# M051BN_v1 register map
File version: 1.0
Registers are 32-bit, read-write, reset 0x0 unless marked. A register's access mark holds for its fields unless they carry their own. Offsets are from the block's base; [hi:lo] are bit positions; {n}, {i} and the like mark numbered series.

## INT — INT Register Map
Base 0x50000300
0x00 IRQ0_SRC ro reset not defined — IRQ0 (BOD) Interrupt Source Identity
  [2:0] INT_SRC — IRQ0 Source Identity. Note: When the interrupt flag is cleared, the corresponding bits will be cleared automatically.
    0=IRQ0 source is not from BOD interrupt (BOD_INT); 1=IRQ0 source is from BOD interrupt (BOD_INT)
0x04 IRQ1_SRC ro reset not defined — IRQ1 (WDT) Interrupt Source Identity
  [2:0] INT_SRC — IRQ1 Source Identity. Note: When the interrupt flag is cleared, the corresponding bits will be cleared automatically.
    0=IRQ1 source is not from watchdog interrupt (WDT _INT); 1=IRQ1 source is from watchdog interrupt (WDT_INT)
0x08 IRQ2_SRC ro reset not defined — IRQ2 (EINT0) Interrupt Source Identity
  [2:0] INT_SRC — IRQ2 Source Identity. Note: When the interrupt flag is cleared, the corresponding bits will be cleared automatically.
    0=IRQ2 source is not from external signal interrupt 0 - P3.2 (EINT0); 1=IRQ2 source is from external signal interrupt 0 - P3.2 (EINT0)
0x0C IRQ3_SRC ro reset not defined — IRQ3 (EINT1) Interrupt Source Identity
  [2:0] INT_SRC — IRQ3 Source Identity. Note: When the interrupt flag is cleared, the corresponding bits will be cleared automatically.
    0=IRQ3 source is not from external signal interrupt 1 - P3.3 (EINT1); 1=IRQ3 source is from external signal interrupt 1 - P3.3 (EINT1)
0x10 IRQ4_SRC ro reset not defined — IRQ4 (P0/1) Interrupt Source Identity
  [2:0] INT_SRC — IRQ4 Source Identity. Note1: IRQ4 source can be from multiple interrupt sources at the same time. Note2: When the interrupt flag is cleared, the corresponding bits will be cleared automatically.
    0=IRQ4 source is not from P1 interrupt (P1_INT). IRQ4 source is not from P0 interrupt (P0_INT); 1=IRQ4 source is from P1 interrupt (P1_INT). IRQ4 source is from P0 interrupt (P0_INT)
0x14 IRQ5_SRC ro reset not defined — IRQ5 (P2/3/4) Interrupt Source Identity
  [2:0] INT_SRC — IRQ5 Source Identity. INT_SRC[2]: Note1: IRQ5 source can be from multiple interrupt sources at the same time. Note2: When the interrupt flag is cleared, the corresponding bits will be cleared automatically.
    0=IRQ5 source is not from P4 interrupt (P4_INT). IRQ5 source is not from P3 interrupt (P3_INT). IRQ5 source is not from P2 interrupt (P2_INT); 1=IRQ5 source is from P4 interrupt (P4_INT). IRQ5 source is from P3 interrupt (P3_INT). IRQ5 source is from P2 interrupt (P2_INT)
0x18 IRQ6_SRC ro reset not defined — IRQ6 (PWMA) Interrupt Source Identity
  [3:0] INT_SRC — IRQ6 Source Identity. INT_SRC[3]: Note1: IRQ6 source can be from multiple interrupt sources at the same time. Note2: When the interrupt flag is cleared, the corresponding bits will be cleared automatically.
    0=IRQ6 source is not from PWM3(PWMA channel 3) interrupt (PWM3_INT). IRQ6 source is not from PWM2(PWMA channel 2) interrupt (PWM2_INT). IRQ6 source is not from PWM1(PWMA channel 1) interrupt (PWM1_INT). IRQ6 source is not from PWM0(PWMA channel 0) interrupt (PWM0_INT); 1=IRQ6 source is from PWM3(PWMA channel 3) interrupt (PWM3_INT). IRQ6 source is from PWM2(PWMA channel 2) interrupt (PWM2_INT). IRQ6 source is from PWM1(PWMA channel 1) interrupt (PWM1_INT). IRQ6 source is from PWM0(PWMA channel 0) interrupt (PWM0_INT)
0x1C IRQ7_SRC ro reset not defined — IRQ7 (PWMB) Interrupt Source Identity
  [3:0] INT_SRC — IRQ7 Source Identity. INT_SRC[3]: Note1: IRQ7 source can be from multiple interrupt sources at the same time. Note2: When the interrupt flag is cleared, the corresponding bits will be cleared automatically.
    0=IRQ7 source is not from PWM7(PWMB channel 3) interrupt (PWM7_INT). IRQ7 source is not from PWM6(PWMB channel 2) interrupt (PWM6_INT). IRQ7 source is not from PWM5(PWMB channel 1) interrupt (PWM5_INT). IRQ7 source is not from PWM4(PWMB channel 0) interrupt (PWM4_INT); 1=IRQ7 source is from PWM7(PWMB channel 3) interrupt (PWM7_INT). IRQ7 source is from PWM6(PWMB channel 2) interrupt (PWM6_INT). IRQ7 source is from PWM5(PWMB channel 1) interrupt (PWM5_INT). IRQ7 source is from PWM4(PWMB channel 0) interrupt (PWM4_INT)
{0x0+4i} IRQ{i}_SRC ro reset not defined (i=8..11) — IRQ{i} (TMR{i-8}) Interrupt Source Identity
  [2:0] INT_SRC — IRQ{i} Source Identity. Note: When the interrupt flag is cleared, the corresponding bits will be cleared automatically.
    0=IRQ{i} source is not from Timer{i-8} interrupt (TMR{i-8}_INT); 1=IRQ{i} source is from Timer{i-8} interrupt (TMR{i-8}_INT)
0x30 IRQ12_SRC ro reset not defined — IRQ12 (UART0) Interrupt Source Identity
  [2:0] INT_SRC — IRQ12 Source Identity. Note: When the interrupt flag is cleared, the corresponding bits will be cleared automatically.
    0=IRQ12 source is not from UART0 interrupt (UART0_INT); 1=IRQ12 source is from UART0 interrupt (UART0_INT)
0x34 IRQ13_SRC ro reset not defined — IRQ13 (UART1) Interrupt Source Identity
  [2:0] INT_SRC — IRQ13 Source Identity. Note: When the interrupt flag is cleared, the corresponding bits will be cleared automatically.
    0=IRQ13 source is not from UART1 interrupt (UART1_INT); 1=IRQ13 source is from UART1 interrupt (UART1_INT)
0x38 IRQ14_SRC ro reset not defined — IRQ14 (SPI0) Interrupt Source Identity
  [2:0] INT_SRC — IRQ14 Source Identity. Note: When the interrupt flag is cleared, the corresponding bits will be cleared automatically.
    0=IRQ14 source is not from SPI0 interrupt (SPI0_INT); 1=IRQ14 source is from SPI0 interrupt (SPI0_INT)
0x3C IRQ15_SRC ro reset not defined — IRQ15 (SPI1) Interrupt Source Identity
  [2:0] INT_SRC — IRQ15 Source Identity. Note: When the interrupt flag is cleared, the corresponding bits will be cleared automatically.
    0=IRQ15 source is not from SPI1 interrupt (SPI1_INT); 1=IRQ15 source is from SPI1 interrupt (SPI1_INT)
0x40 IRQ16_SRC ro reset not defined — Reserved.
0x44 IRQ17_SRC ro reset not defined — Reserved.
0x48 IRQ18_SRC ro reset not defined — IRQ18 (I2C0) Interrupt Source Identity
  [2:0] INT_SRC — IRQ18 Source Identity. Note: When the interrupt flag is cleared, the corresponding bits will be cleared automatically.
    0=IRQ18 source is not from I2C0 interrupt (I2C0_INT); 1=IRQ18 source is from I2C0 interrupt (I2C0_INT)
0x4C IRQ19_SRC ro reset not defined — IRQ19 (I2C1) Interrupt Source Identity (M05xxDN/DE Only)
  [2:0] INT_SRC — IRQ19 Source Identity (M05xxDN/DE Only). Note: When the interrupt flag is cleared, the corresponding bits will be cleared automatically.
    0=IRQ19 source is not from I2C1 interrupt (I2C1_INT); 1=IRQ19 source is from I2C1 interrupt (I2C1_INT)
{0x0+4i} IRQ{i}_SRC ro reset not defined (i=20..24) — Reserved.
0x64 IRQ25_SRC ro reset not defined — IRQ25 (ACMP01) Interrupt Source Identity
  [2:0] INT_SRC — IRQ25 Source Identity. Note: When the interrupt flag is cleared, the corresponding bits will be cleared automatically.
    0=IRQ25 source is not from ACMP01 interrupt (ACMP01_INT); 1=IRQ25 source is from ACMP01 interrupt (ACMP01_INT)
0x68 IRQ26_SRC ro reset not defined — IRQ26 (ACMP23) Interrupt Source Identity (M05xxDN/DE Only)
  [2:0] INT_SRC — IRQ26 Source Identity (M05xxDN/DE Only). Note: When the interrupt flag is cleared, the corresponding bits will be cleared automatically.
    0=IRQ26 source is not from ACMP23 interrupt (ACMP23_INT); 1=IRQ26 source is from ACMP23 interrupt (ACMP23_INT)
0x6C IRQ27_SRC ro reset not defined — Reserved.
0x70 IRQ28_SRC ro reset not defined — IRQ28 (PWRWU) Interrupt Source Identity
  [2:0] INT_SRC — IRQ28 Source Identity. Note: When the interrupt flag is cleared, the corresponding bits will be cleared automatically.
    0=IRQ28 source is not from Power-down mode Wake-up interrupt (PWRWU_INT); 1=IRQ28 source is from Power-down mode Wake-up interrupt interrupt (PWRWU_INT)
0x74 IRQ29_SRC ro reset not defined — IRQ29 (ADC) Interrupt Source Identity
  [2:0] INT_SRC — IRQ29 Source Identity. Note: When the interrupt flag is cleared, the corresponding bits will be cleared automatically.
    0=IRQ29 source is not from ADC interrupt (ADC_INT); 1=IRQ29 source is from ADC interrupt (ADC_INT)
0x78 IRQ30_SRC ro reset not defined — Reserved.
0x7C IRQ31_SRC ro reset not defined — Reserved.
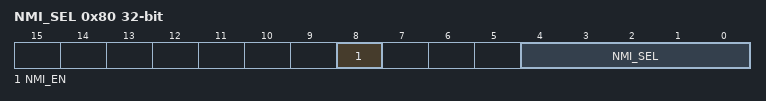
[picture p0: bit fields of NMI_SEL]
0x80 NMI_SEL — NMI Source Interrupt Select Control Register
  [8] NMI_EN — NMI Interrupt Enable Control (Write Protect). Note: This bit is the protected bit and programming it needs to write "59h", "16h", and "88h" to address 0x5000_0100 to disable register protection. Reference the register REGWRPROT at address GCR_BA+0x100
    0=NMI interrupt Disabled; 1=NMI interrupt Enabled
  [4:0] NMI_SEL — NMI Interrupt Source Selection. The NMI interrupt to Cortex-M0 can be selected from one of the peripheral interrupt by setting NMI_SEL.
